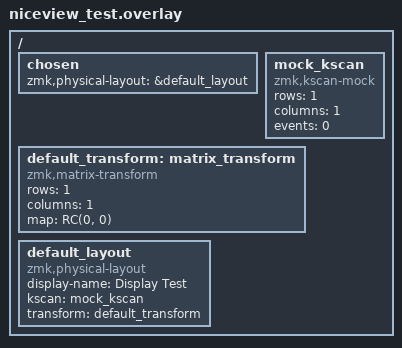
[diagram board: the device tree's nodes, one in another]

#include <dt-bindings/zmk/matrix_transform.h>

/ {
    chosen {
        zmk,physical-layout = &default_layout;
    };

    mock_kscan: mock_kscan {
        compatible = "zmk,kscan-mock";
        rows = <1>;
        columns = <1>;
        events = <0>;
    };

    default_transform: matrix_transform {
        compatible = "zmk,matrix-transform";
        rows = <1>;
        columns = <1>;
        map = <RC(0, 0)>;
    };

    default_layout: default_layout {
        compatible = "zmk,physical-layout";
        display-name = "Display Test";
        kscan = <&mock_kscan>;
        transform = <&default_transform>;
    };
};
